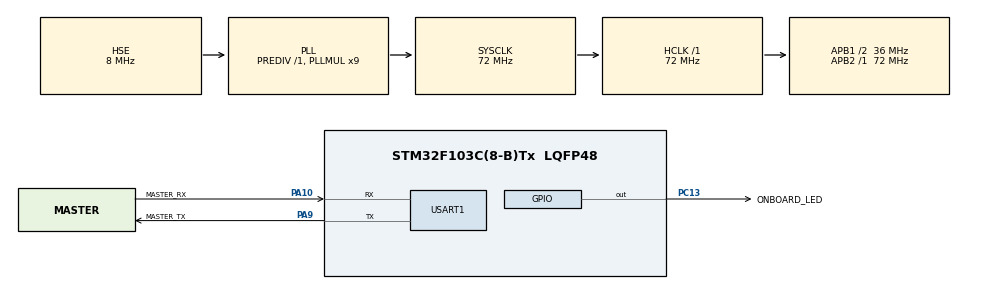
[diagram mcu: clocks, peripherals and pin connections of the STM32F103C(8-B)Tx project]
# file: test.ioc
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Dma.Request0=USART1_TX
Dma.USART1_TX.0.Direction=DMA_MEMORY_TO_PERIPH
Dma.USART1_TX.0.Instance=DMA1_Channel4
Dma.USART1_TX.0.MemDataAlignment=DMA_MDATAALIGN_BYTE
Dma.USART1_TX.0.MemInc=DMA_MINC_ENABLE
Dma.USART1_TX.0.Mode=DMA_NORMAL
Dma.USART1_TX.0.PeriphDataAlignment=DMA_PDATAALIGN_BYTE
Dma.USART1_TX.0.PeriphInc=DMA_PINC_DISABLE
Dma.USART1_TX.0.Priority=DMA_PRIORITY_LOW
Mcu.Family=STM32F1
Mcu.Name=STM32F103C(8-B)Tx
Mcu.Package=LQFP48
NVIC.DMA1_Channel4_IRQn=true\:0\:0\:false\:false\:true\:false\:true
NVIC.PriorityGroup=NVIC_PRIORITYGROUP_4
NVIC.USART1_IRQn=true\:0\:0\:false\:false\:true\:true\:true
PA10.GPIO_Label=MASTER_RX
PA10.Mode=Asynchronous
PA10.Signal=USART1_RX
PA13.Mode=Serial_Wire
PA13.Signal=SYS_JTMS-SWDIO
PA14.Mode=Serial_Wire
PA14.Signal=SYS_JTCK-SWCLK
PA9.GPIO_Label=MASTER_TX
PA9.Mode=Asynchronous
PA9.Signal=USART1_TX
PB3.Signal=SYS_JTDO-TRACESWO
PC13-TAMPER-RTC.GPIO_Label=ONBOARD_LED
PC13-TAMPER-RTC.GPIO_ModeDefaultOutputPP=GPIO_MODE_OUTPUT_PP
PC13-TAMPER-RTC.PinState=GPIO_PIN_SET
PC13-TAMPER-RTC.Signal=GPIO_Output
PD0-OSC_IN.Mode=HSE-External-Oscillator
PD0-OSC_IN.Signal=RCC_OSC_IN
PD1-OSC_OUT.Mode=HSE-External-Oscillator
PD1-OSC_OUT.Signal=RCC_OSC_OUT
ProjectManager.HeapSize=0x200
ProjectManager.StackSize=0x400
ProjectManager.TargetToolchain=EWARM V8.32
RCC.AHBFreq_Value=72000000
RCC.APB1CLKDivider=RCC_HCLK_DIV2
RCC.APB1Freq_Value=36000000
RCC.APB1TimFreq_Value=72000000
RCC.APB2Freq_Value=72000000
RCC.APB2TimFreq_Value=72000000
RCC.HCLKFreq_Value=72000000
RCC.PLLMUL=RCC_PLL_MUL9
RCC.PLLSourceVirtual=RCC_PLLSOURCE_HSE
RCC.SYSCLKFreq_VALUE=72000000
RCC.SYSCLKSource=RCC_SYSCLKSOURCE_PLLCLK
RCC.USBFreq_Value=72000000
USART1.VirtualMode=VM_ASYNC
board=custom

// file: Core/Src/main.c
/* USER CODE BEGIN Header */
/**
  ******************************************************************************
  * @file           : main.c
  * @brief          : Main program body
  ******************************************************************************
  * @attention
  *
  * <h2><center>&copy; Copyright (c) 2020 STMicroelectronics.
  * All rights reserved.</center></h2>
  *
  * This software component is licensed by ST under BSD 3-Clause license,
  * the "License"; You may not use this file except in compliance with the
  * License. You may obtain a copy of the License at:
  *                        opensource.org/licenses/BSD-3-Clause
  *
  ******************************************************************************
  */
/* USER CODE END Header */
#include "main.h"

/* USER CODE BEGIN Includes */
#include "dataEx.h"
#include <stdio.h>
/* USER CODE END Includes */

/* USER CODE BEGIN PV */
UART_HandleTypeDef huart1;
DMA_HandleTypeDef hdma_usart1_tx;
static uint8_t toTxBuf[]="Please send me a packet, then I pack it as DATA and return it back\r\n";
unsigned char inBox[sizeof(receive_Buf_t)];
/* USER CODE END PV */

void SystemClock_Config(void);
static void MX_GPIO_Init(void);
static void MX_DMA_Init(void);
static void MX_USART1_UART_Init(void);

int main(void)
{

  /* MCU Configuration--------------------------------------------------------*/

  /* Reset of all peripherals, Initializes the Flash interface and the Systick. */
  HAL_Init();

  /* Configure the system clock */
  SystemClock_Config();

  /* Initialize all configured peripherals */
  MX_GPIO_Init();
  MX_DMA_Init();
  MX_USART1_UART_Init();
  /* USER CODE BEGIN 2 */

  printf("Let start\r\n");
  HAL_GPIO_WritePin(ONBOARD_LED_GPIO_Port, ONBOARD_LED_Pin, GPIO_PIN_SET);

  if (uart_handle_registr(&huart1) != STATUS_OK)
    Error_Handler();
  // ----------------- test begin ------------------
  // send prompt
   if (send_request(CMD_EXAMPLE, toTxBuf, sizeof(toTxBuf)-1) != STATUS_OK)
     Error_Handler();

  /* USER CODE END 2 */

  /* Infinite loop */
  /* USER CODE BEGIN WHILE */
  while (1)
  {
     int16_t msglen=0;
     if ((msglen = polling())>0)  //check incoming
     {
       printf("\r\n_message %d bytes\r\n",msglen);
       if (process_answer (inBox) == STATUS_OK)
       {
         //displaying
        for (uint16_t i=0; i<msglen; i++)
          printf("0x%X ",*(inBox + i));

        HAL_Delay(50); //immitate delay

        HAL_GPIO_WritePin(ONBOARD_LED_GPIO_Port, ONBOARD_LED_Pin, GPIO_PIN_SET);  //LED error indicate OFF

        //Repacking inBox as new outgong packet and send back
        while (send_request(31, inBox, msglen) != STATUS_OK)
          asm("nop"); //try send
       }//  STATUS_OK
        else
        {
          printf("CRC wrong\r\n");
          HAL_GPIO_WritePin(ONBOARD_LED_GPIO_Port, ONBOARD_LED_Pin, GPIO_PIN_RESET);  //LED error indicate ON
        }
     } //polling()>0
    /* USER CODE END WHILE */

  }
}

void SystemClock_Config(void)
{
  RCC_OscInitTypeDef RCC_OscInitStruct = {0};
  RCC_ClkInitTypeDef RCC_ClkInitStruct = {0};

  /** Initializes the RCC Oscillators according to the specified parameters
  * in the RCC_OscInitTypeDef structure.
  */
  RCC_OscInitStruct.OscillatorType = RCC_OSCILLATORTYPE_HSE;
  RCC_OscInitStruct.HSEState = RCC_HSE_ON;
  RCC_OscInitStruct.HSEPredivValue = RCC_HSE_PREDIV_DIV1;
  RCC_OscInitStruct.HSIState = RCC_HSI_ON;
  RCC_OscInitStruct.PLL.PLLState = RCC_PLL_ON;
  RCC_OscInitStruct.PLL.PLLSource = RCC_PLLSOURCE_HSE;
  RCC_OscInitStruct.PLL.PLLMUL = RCC_PLL_MUL9;
  if (HAL_RCC_OscConfig(&RCC_OscInitStruct) != HAL_OK)
  {
    Error_Handler();
  }
  /** Initializes the CPU, AHB and APB buses clocks
  */
  RCC_ClkInitStruct.ClockType = RCC_CLOCKTYPE_HCLK|RCC_CLOCKTYPE_SYSCLK
                              |RCC_CLOCKTYPE_PCLK1|RCC_CLOCKTYPE_PCLK2;
  RCC_ClkInitStruct.SYSCLKSource = RCC_SYSCLKSOURCE_PLLCLK;
  RCC_ClkInitStruct.AHBCLKDivider = RCC_SYSCLK_DIV1;
  RCC_ClkInitStruct.APB1CLKDivider = RCC_HCLK_DIV2;
  RCC_ClkInitStruct.APB2CLKDivider = RCC_HCLK_DIV1;

  if (HAL_RCC_ClockConfig(&RCC_ClkInitStruct, FLASH_LATENCY_2) != HAL_OK)
  {
    Error_Handler();
  }
}

static void MX_USART1_UART_Init(void)
{

  huart1.Instance = USART1;
  huart1.Init.BaudRate = 115200;
  huart1.Init.WordLength = UART_WORDLENGTH_8B;
  huart1.Init.StopBits = UART_STOPBITS_1;
  huart1.Init.Parity = UART_PARITY_NONE;
  huart1.Init.Mode = UART_MODE_TX_RX;
  huart1.Init.HwFlowCtl = UART_HWCONTROL_NONE;
  huart1.Init.OverSampling = UART_OVERSAMPLING_16;
  if (HAL_UART_Init(&huart1) != HAL_OK)
  {
    Error_Handler();
  }

}

static void MX_DMA_Init(void)
{

  /* DMA controller clock enable */
  __HAL_RCC_DMA1_CLK_ENABLE();

  /* DMA interrupt init */
  /* DMA1_Channel4_IRQn interrupt configuration */
  HAL_NVIC_SetPriority(DMA1_Channel4_IRQn, 0, 0);
  HAL_NVIC_EnableIRQ(DMA1_Channel4_IRQn);

}

static void MX_GPIO_Init(void)
{
  GPIO_InitTypeDef GPIO_InitStruct = {0};

  /* GPIO Ports Clock Enable */
  __HAL_RCC_GPIOC_CLK_ENABLE();
  __HAL_RCC_GPIOD_CLK_ENABLE();
  __HAL_RCC_GPIOA_CLK_ENABLE();
  __HAL_RCC_GPIOB_CLK_ENABLE();

  /*Configure GPIO pin Output Level */
  HAL_GPIO_WritePin(ONBOARD_LED_GPIO_Port, ONBOARD_LED_Pin, GPIO_PIN_RESET);

  /*Configure GPIO pin : ONBOARD_LED_Pin */
  GPIO_InitStruct.Pin = ONBOARD_LED_Pin;
  GPIO_InitStruct.Mode = GPIO_MODE_OUTPUT_PP;
  GPIO_InitStruct.Pull = GPIO_NOPULL;
  GPIO_InitStruct.Speed = GPIO_SPEED_FREQ_LOW;
  HAL_GPIO_Init(ONBOARD_LED_GPIO_Port, &GPIO_InitStruct);

}

void Error_Handler(void)
{
  /* USER CODE BEGIN Error_Handler_Debug */
  printf("_Caught in HAL error handler\r\n");
  while(1)
    asm("nop");

  /* USER CODE END Error_Handler_Debug */
}

#ifdef  USE_FULL_ASSERT
/**
  * @brief  Reports the name of the source file and the source line number
  *         where the assert_param error has occurred.
  * @param  file: pointer to the source file name
  * @param  line: assert_param error line source number
  * @retval None
  */
void assert_failed(uint8_t *file, uint32_t line)
{
  /* USER CODE BEGIN 6 */
  while(1)
    asm("nop");
  /* User can add his own implementation to report the file name and line number,
     tex: printf("Wrong parameters value: file %s on line %d\r\n", file, line) */
  /* USER CODE END 6 */
}
#endif /* USE_FULL_ASSERT */

/************************ (C) COPYRIGHT STMicroelectronics *****END OF FILE****/
